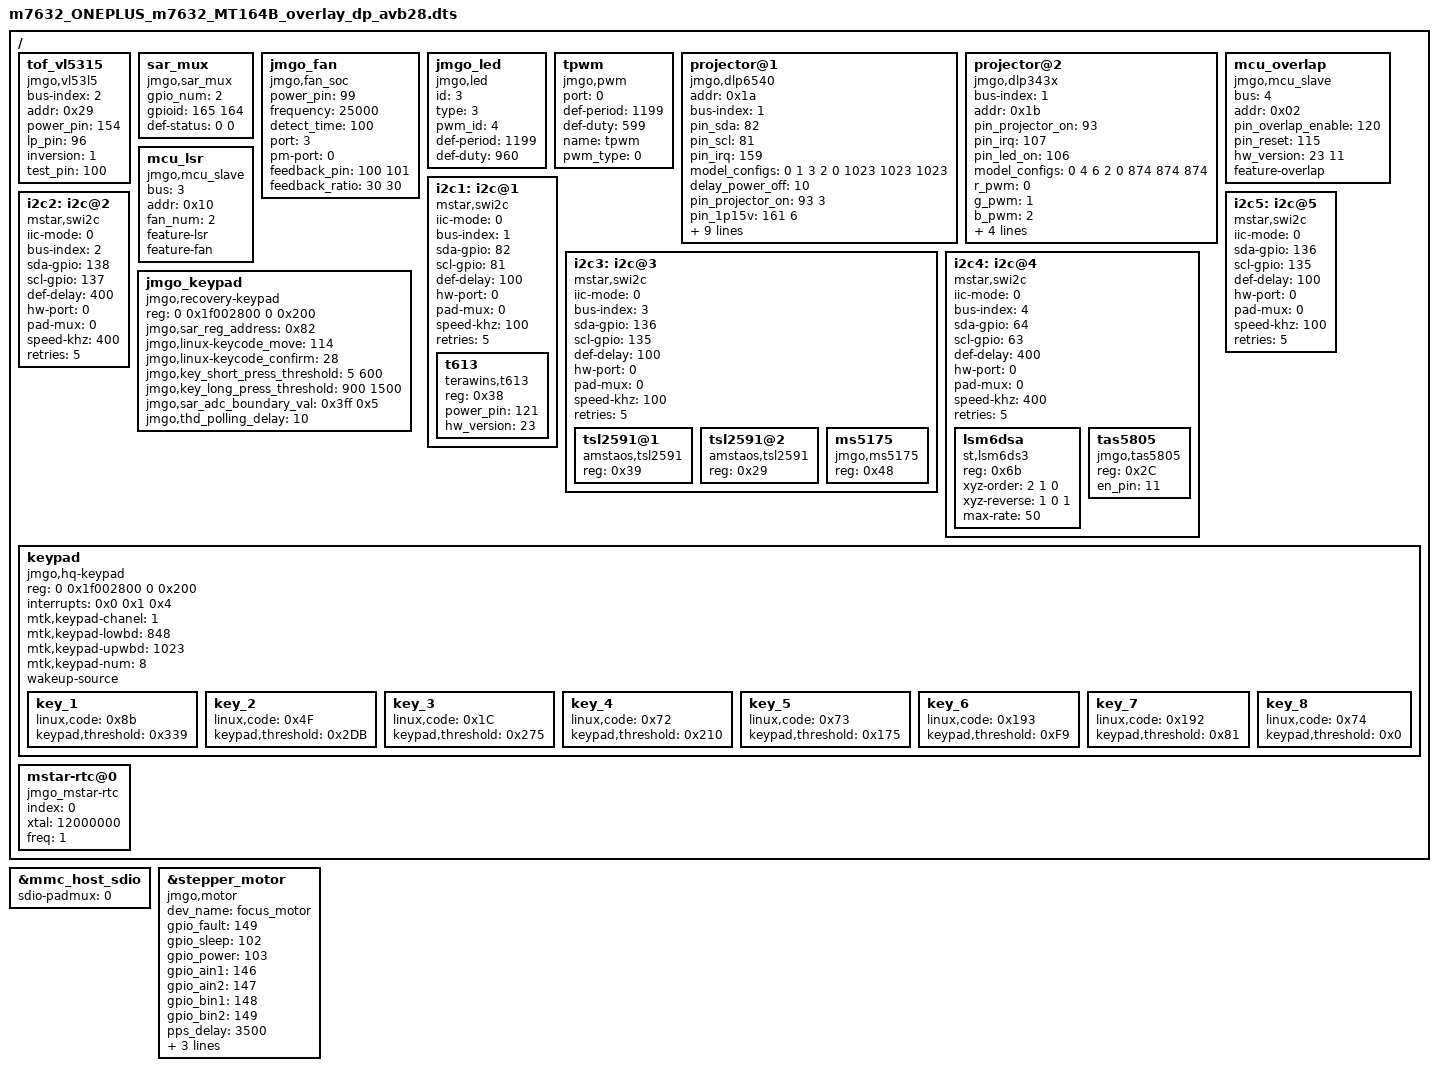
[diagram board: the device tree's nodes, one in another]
/dts-v1/;
/plugin/;
/include/ "overlay_avb_SysAsRoot.dtsi"

/ {
  fragment@10 {
        target-path = "/";
        __overlay__ {
            tof_vl5315 {
                compatible = "jmgo,vl53l5";
                bus-index = <2>;
                addr = <0x29>;
                power_pin = <154>; // PAD_TS0_VLD
                lp_pin = <96>; // PAD_PCM2_WAIT_N
                inversion = <1>;
                test_pin = <100>;
                status = "okay";
            };
        };
    };

  fragment@11 {
        target-path = "/";
        __overlay__ {
            sar_mux {
                status = "okay";
                compatible = "jmgo,sar_mux";
                gpio_num = <2>;
                gpioid = <165 164>;// PAD_TS1_VLD, PAD_TS1_SYNC
                def-status = <0 0>;
            };
        };
    };

  fragment@12 {
        target-path = "/";
        __overlay__ {
            jmgo_fan {
                status = "okay";
                compatible = "jmgo,fan_soc";
                power_pin = <99>; //PAD_PCM_A2 电源控制引脚，可选
                frequency = <25000>; // PWM频率(Hz)，可选，默认25000
                detect_time = <100>; // 脉冲检测时间(ms)，可选，默认100
                port = <3>;
                pm-port = <0>;
                feedback_pin = <100 101>; //PAD_PCM_A3 PAD_PCM_A4 风扇反馈引脚，数组长度保持和port一致
                feedback_ratio = <30 30>; // 风扇反馈速度系数，数组长度保持和port一致
            };
        };
    };

  fragment@13 {
        target-path = "/";
        __overlay__ {
            jmgo_led {
                status = "okay";
                compatible = "jmgo,led";
                id = <3>; // 0: blue, 1: green, 2: red, 3: white
                type = <3>; // 0:pwm, 1:pm_pwm, 2:sw_pwm, 3:gpio
                pwm_id = <4>; // gpio id
                def-period = <1199>; // pwm period
                def-duty = <960>; // pwm duty
            };
        };
    };

  fragment@14 {
        target-path = "/";
        __overlay__ {
            tpwm {
                status = "okay";
                compatible = "jmgo,pwm";
                port = <0>;
                def-period = <1199>; // 10k
                def-duty = <599>;    //0%
                name = "tpwm";
                pwm_type = <0>;
            }; 
        };
  };

  fragment@15 {
        target-path = "/";
        __overlay__ {
            projector@1 {
                compatible = "jmgo,dlp6540";
                addr = <0x1a>;
                bus-index = <1>;
                pin_sda = <82>;
                pin_scl = <81>; // PAD_I2S_OUT_SD1
                pin_irq = <159>; // PAD_TS1_D3
                model_configs = <0 /* dlp model */ 1 3 2 0 /* flip */  1023 1023 1023 /* max current */ >;
                delay_power_off = <10>;
                pin_projector_on  = <93 3>; // PAC_PCM2_CD_N
                pin_1p15v = <161 6>; // PAD_TS1_D5
                pin_1p8v = <163 6>; // PAD_TS1_D7
                pin_3p3v = <155 6>; // PAD_TS1_CLK
                pin_1p21v = <162 10>; // PAD_TS1_D6
                pin_act_on = <153>; // PAD_TS0_SYNC
                laser_control;
                args = "flip=0,brightness_value=1023,1023,1023,0,look=0,display_size=H:3840-V:2160,dlpModel=0";
                init_on_probe;
                hw_version = <31>;
            };
            projector@2 {
                compatible = "jmgo,dlp343x";
                bus-index = <1>;
                addr = <0x1b>;
                pin_projector_on = <93>;
                pin_irq = <107>;//PAD_PCM_A10
                pin_led_on = <106>;//PAD_PCM_A9 NOT USED PIN!
                model_configs = <0  4 6 2 0  874 874 874>;
                r_pwm = <0>;
                g_pwm = <1>;
                b_pwm = <2>;
                pwm_period = <537>;
                args = "flip=0,brightness_value=255,255,255,0,look=0,display_size=H:1920-V:1080,dlpModel=0";
                hw_version = <23 11>;
            };
        };
  };
  fragment@25 {
        target-path = "/";
        __overlay__ {
            mcu_overlap {
                compatible = "jmgo,mcu_slave";
                bus = <4>;
                addr = <0x02>;
                pin_overlap_enable = <120/* PCM_D6*/ >;
                pin_reset = <115 /* PCM_D1 */>;
                hw_version = <23 11>;
                feature-overlap;
            };
            mcu_lsr {
                compatible = "jmgo,mcu_slave";
                bus = <3>;
                addr = <0x10>;
                fan_num = <2>;
                feature-lsr;
                feature-fan;
            };
        };
  };

  // dlp
  fragment@16 {
      target-path = "/";
      __overlay__ {
        i2c1: i2c@1 {
          compatible = "mstar,swi2c";
          status = "okay";    /* Unused */
          iic-mode = <0>;     /* i2c-mode: 0:swi2c; 1:hwi2c */
          bus-index = <1>;    /* swi2c setting: bus index */
          sda-gpio = <82>;   /* swi2c setting: sda pad */
          scl-gpio = <81>;   /* swi2c setting: scl pad */
          def-delay = <100>;  /* swi2c setting: clk */
          hw-port = <0>;      /* hwi2c setting: port */
          pad-mux = <0>;      /* hwi2c setting: pad mux */
          speed-khz = <100>;  /* hwi2c setting: clk */
          retries = <5>;      /* Unused */

          t613 {
            compatible = "terawins,t613";
            reg = <0x38>;
            power_pin = <121>; // PAD_PCM_D7
            hw_version = <23>;
          };
        };
    };
  };

  // area-tof
  fragment@17 {
      target-path = "/";
      __overlay__ {
      i2c2: i2c@2 {
          compatible = "mstar,swi2c";
          status = "okay";    /* Unused */
          iic-mode = <0>;     /* i2c-mode: 0:swi2c; 1:hwi2c */
          bus-index = <2>;    /* swi2c setting: bus index */
          sda-gpio = <138>;   /* swi2c setting: sda pad */
          scl-gpio = <137>;   /* swi2c setting: scl pad */
          def-delay = <400>;  /* swi2c setting: clk */
          hw-port = <0>;      /* hwi2c setting: port */
          pad-mux = <0>;      /* hwi2c setting: pad mux */
          speed-khz = <400>;  /* hwi2c setting: clk */
          retries = <5>;      /* Unused */
      };
      };
  };


  // tmr & als
  fragment@18 {
      target-path = "/";
      __overlay__ {
      i2c3: i2c@3 {
          compatible = "mstar,swi2c";
          status = "okay";    /* Unused */
          iic-mode = <0>;     /* i2c-mode: 0:swi2c; 1:hwi2c */
          bus-index = <3>;    /* swi2c setting: bus index */
          sda-gpio = <136>;   /* swi2c setting: sda pad */
          scl-gpio = <135>;   /* swi2c setting: scl pad */
          def-delay = <100>;  /* swi2c setting: clk */
          hw-port = <0>;      /* hwi2c setting: port */
          pad-mux = <0>;      /* hwi2c setting: pad mux */
          speed-khz = <100>;  /* hwi2c setting: clk */
          retries = <5>;      /* Unused */
          tsl2591@1 {
              compatible = "amstaos,tsl2591";
              reg = <0x39>;
          };
          tsl2591@2 {
              compatible = "amstaos,tsl2591";
              reg = <0x29>;
          };
          ms5175 {
              compatible = "jmgo,ms5175";
              reg = <0x48>;
          };
      };
      };
  };

  // sensor & amp
  fragment@19 {
      target-path = "/";
      __overlay__ {
      i2c4: i2c@4 {
          compatible = "mstar,swi2c";
          status = "okay";    /* Unused */
          iic-mode = <0>;     /* i2c-mode: 0:swi2c; 1:hwi2c */
          bus-index = <4>;    /* swi2c setting: bus index */
          sda-gpio = <64>;   /* swi2c setting: sda pad */
          scl-gpio = <63>;   /* swi2c setting: scl pad */
          def-delay = <400>;  /* swi2c setting: clk */
          hw-port = <0>;      /* hwi2c setting: port */
          pad-mux = <0>;      /* hwi2c setting: pad mux */
          speed-khz = <400>;  /* hwi2c setting: clk */
          retries = <5>;      /* Unused */
          lsm6dsa {
              compatible = "st,lsm6ds3";
              reg = <0x6b>;
	      xyz-order = /bits/ 8 <2 1 0>;
	      xyz-reverse = /bits/ 8 <1 0 1>;
	      max-rate = <50>;  
          };
	        tas5805 {
              compatible = "jmgo,tas5805";
              reg = <0x2C>;
              en_pin = <11>;
          };
      };
      };
  };

  // mcu
  fragment@20 {
      target-path = "/";
      __overlay__ {
      i2c5: i2c@5 {
          compatible = "mstar,swi2c";
          iic-mode = <0>;     /* i2c-mode: 0:swi2c; 1:hwi2c */
         // bus-index = <5>;    /* swi2c setting: bus index */
          sda-gpio = <136>;   /* swi2c setting: sda pad */
          scl-gpio = <135>;   /* swi2c setting: scl pad */
          def-delay = <100>;  /* swi2c setting: clk */
          hw-port = <0>;      /* hwi2c setting: port */
          pad-mux = <0>;      /* hwi2c setting: pad mux */
          speed-khz = <100>;  /* hwi2c setting: clk */
          retries = <5>;      /* Unused */
          status = "okay";    /* Unused */
      };
      };
  };

// jmgo-keypad
  fragment@21 {
        target-path = "/";
        __overlay__ {
            jmgo_keypad {
                compatible = "jmgo,recovery-keypad";
                reg = <0 0x1f002800 0 0x200>; // bank 0x14
                jmgo,sar_reg_address = <0x82>; // sar1.
                jmgo,linux-keycode_move = <114>; // KEY_VOLUMEDOWN
                jmgo,linux-keycode_confirm = <28>; // KEY_ENTER
                jmgo,key_short_press_threshold = <5 600>;
                jmgo,key_long_press_threshold = <900 1500>;
                jmgo,sar_adc_boundary_val = <0x3ff 0x5>;
                jmgo,thd_polling_delay = <10>;
            };
        };
  };

// mtk-keypad overlay
  fragment@22 {
        target-path = "/";
        __overlay__ {
            keypad {
		    compatible = "jmgo,hq-keypad";
		    //compatible = "mtk,hq-keypad";
		    reg = <0 0x1f002800 0 0x200>;
		    interrupts = <0x0 0x1 0x4>;
		    mtk,keypad-chanel = <1>;
		    mtk,keypad-lowbd = <848>;
		    mtk,keypad-upwbd = <1023>;
		    mtk,keypad-num = <8>;
		    wakeup-source;

		    key_1 {
			    linux,code = <0x8b>;
			    keypad,threshold = <0x339>;
		    };

		    key_2 {
			    linux,code = <0x4F>;
			    keypad,threshold = <0x2DB>;
		    };

		    key_3 {
			    linux,code = <0x1C>;
			    keypad,threshold = <0x275>;
		    };

		    key_4 {
			    linux,code = <0x72>;
			    keypad,threshold = <0x210>;
		    };

		    key_5 {
			    linux,code = <0x73>;
			    keypad,threshold = <0x175>;
		    };

		    key_6 {
			    linux,code = <0x193>;
			    keypad,threshold = <0xF9>;
		    };

		    key_7 {
			    linux,code = <0x192>;
			    keypad,threshold = <0x81>;
		    };

		    key_8 {
			    linux,code = <0x74>;
			    keypad,threshold = <0x0>;
		    };

	    };
	};
  };

// jmgo-rtc
  fragment@23 {
        target-path = "/";
        __overlay__ {
            mstar-rtc@0 {
		compatible = "jmgo_mstar-rtc";
		index = <0>;
		xtal = <12000000>;
		freq = <1>;
            };
        };
  };


};

/* overlay main dts */
&mmc_host_sdio {
    sdio-padmux = <0>;
};

&stepper_motor {
    compatible = "jmgo,motor";
    dev_name = "focus_motor";
    status = "okay";
    gpio_fault = <149>; // not used
    gpio_sleep = <102>; // PAD_PCM_A5
    gpio_power = <103>; //PAD_PCM_A6
    gpio_ain1 = <146>;//PAD_TS0_D1
    gpio_ain2 = <147>;//PAD_TS0_D2
    gpio_bin1 = <148>;//PAD_TS0_D3
    gpio_bin2 = <149>;//PAD_TS0_D4
    pps_delay = <3500>;
    auto_pps_delay = <2000>;
    // phase:   ain1, bin1, ain2, bin2
    beatdata = /bits/ 8 < /* step 1 */ 1     0     0    1
        /* step 2 */ 0     0     0    1
        /* step 3 */ 0     0     1    1
        /* step 4 */ 0     0     1    0
        /* step 5 */ 0     1     1    0
        /* step 6 */ 0     1     0    0
        /* step 7 */ 1     1     0    0
        /* step 8 */ 1     0     0    0>;
};
